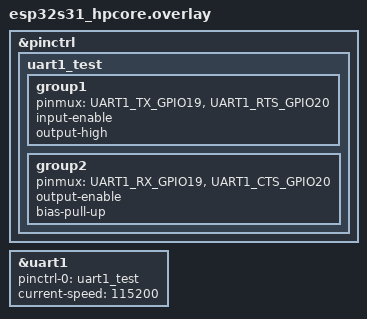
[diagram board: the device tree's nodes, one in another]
/*
 * Copyright (c) 2026 Espressif Systems (Shanghai) Co., Ltd.
 *
 * SPDX-License-Identifier: Apache-2.0
 */

&pinctrl {
	uart1_test: uart1_test {
		group1 {
			pinmux = <UART1_TX_GPIO19>,
				 <UART1_RTS_GPIO20>;
			input-enable;
			output-high;
		};

		group2 {
			pinmux = <UART1_RX_GPIO19>,
				 <UART1_CTS_GPIO20>;
			output-enable;
			bias-pull-up;
		};
	};
};

dut: &uart1 {
	status = "okay";
	pinctrl-0 = <&uart1_test>;
	pinctrl-names = "default";
	current-speed = <115200>;
};
